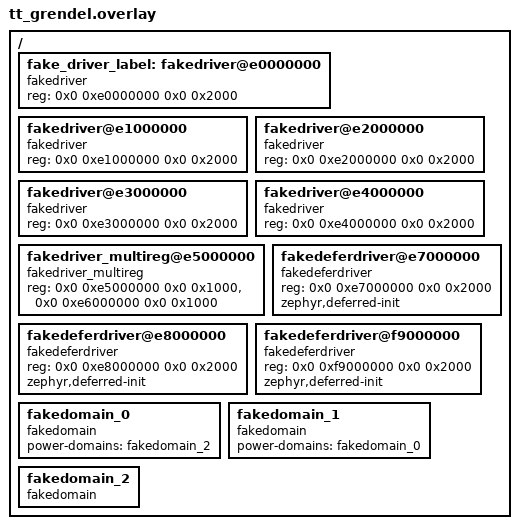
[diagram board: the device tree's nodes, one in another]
/*
 * Copyright (c) 2026 Tenstorrent AI ULC
 * SPDX-License-Identifier: Apache-2.0
 *
 * Replacement for zephyr/tests/kernel/device/app.overlay on Grendel SMCs. Upstream forces the root
 * to #address-cells/#size-cells = <1>, which reinterprets this SoC's 2-cell memory nodes (SRAM
 * becomes base 0x0) and links the image at address 0. Same fake nodes, with 2-cell reg values.
 */

/ {
	fake_driver_label: fakedriver@e0000000 {
		compatible = "fakedriver";
		reg = <0x0 0xe0000000 0x0 0x2000>;
		status = "okay";
	};

	fakedriver@e1000000 {
		compatible = "fakedriver";
		reg = <0x0 0xe1000000 0x0 0x2000>;
		status = "okay";
	};

	fakedriver@e2000000 {
		compatible = "fakedriver";
		reg = <0x0 0xe2000000 0x0 0x2000>;
		status = "okay";
	};

	fakedriver@e3000000 {
		compatible = "fakedriver";
		reg = <0x0 0xe3000000 0x0 0x2000>;
		status = "okay";
	};

	fakedriver@e4000000 {
		compatible = "fakedriver";
		reg = <0x0 0xe4000000 0x0 0x2000>;
		status = "okay";
	};

	fakedriver_multireg@e5000000 {
		compatible = "fakedriver_multireg";
		reg = <0x0 0xe5000000 0x0 0x1000>,
		      <0x0 0xe6000000 0x0 0x1000>;
		reg-names = "chip",
			    "dale";
		status = "okay";
	};

	fakedeferdriver@e7000000 {
		compatible = "fakedeferdriver";
		reg = <0x0 0xe7000000 0x0 0x2000>;
		status = "okay";
		zephyr,deferred-init;
	};

	fakedeferdriver@e8000000 {
		compatible = "fakedeferdriver";
		reg = <0x0 0xe8000000 0x0 0x2000>;
		status = "okay";
		zephyr,deferred-init;
	};

	fakedeferdriver@f9000000 {
		compatible = "fakedeferdriver";
		reg = <0x0 0xf9000000 0x0 0x2000>;
		status = "okay";
		zephyr,deferred-init;
	};

	fakedomain_0: fakedomain_0 {
		compatible = "fakedomain";
		status = "okay";
		power-domains = <&fakedomain_2>;
		#power-domain-cells = <0>;
	};

	fakedomain_1: fakedomain_1 {
		compatible = "fakedomain";
		status = "okay";
		power-domains = <&fakedomain_0>;
		#power-domain-cells = <0>;
	};

	fakedomain_2: fakedomain_2 {
		compatible = "fakedomain";
		status = "okay";
		#power-domain-cells = <0>;
	};
};
